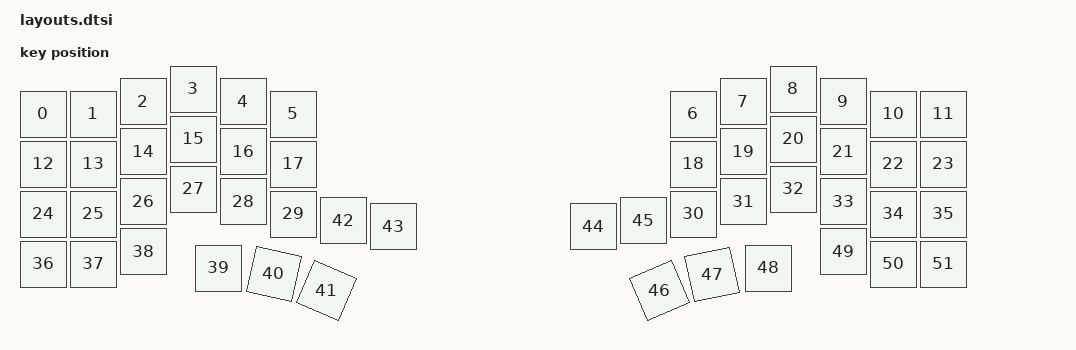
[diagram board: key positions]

#include <physical_layouts.dtsi>
/ {
    physical_layout0: physical_layout0 {
        compatible = "zmk,physical-layout";
        display-name = "Layout";
        keys
            = <&key_physical_attrs 100 100 0 100 0 0 0>
			,<&key_physical_attrs 100 100 100 100 0 0 0>
			,<&key_physical_attrs 100 100 200 75 0 0 0>
			,<&key_physical_attrs 100 100 300 50 0 0 0>
			,<&key_physical_attrs 100 100 400 75 0 0 0>
			,<&key_physical_attrs 100 100 500 100 0 0 0>
			,<&key_physical_attrs 100 100 1300 100 0 0 0>
			,<&key_physical_attrs 100 100 1400 75 0 0 0>
			,<&key_physical_attrs 100 100 1500 50 0 0 0>
			,<&key_physical_attrs 100 100 1600 75 0 0 0>
			,<&key_physical_attrs 100 100 1700 100 0 0 0>
			,<&key_physical_attrs 100 100 1800 100 0 0 0>
			,<&key_physical_attrs 100 100 0 200 0 0 0>
			,<&key_physical_attrs 100 100 100 200 0 0 0>
			,<&key_physical_attrs 100 100 200 175 0 0 0>
			,<&key_physical_attrs 100 100 300 150 0 0 0>
			,<&key_physical_attrs 100 100 400 175 0 0 0>
			,<&key_physical_attrs 100 100 500 200 0 0 0>
			,<&key_physical_attrs 100 100 1300 200 0 0 0>
			,<&key_physical_attrs 100 100 1400 175 0 0 0>
			,<&key_physical_attrs 100 100 1500 150 0 0 0>
			,<&key_physical_attrs 100 100 1600 175 0 0 0>
			,<&key_physical_attrs 100 100 1700 200 0 0 0>
			,<&key_physical_attrs 100 100 1800 200 0 0 0>
			,<&key_physical_attrs 100 100 0 300 0 0 0>
			,<&key_physical_attrs 100 100 100 300 0 0 0>
			,<&key_physical_attrs 100 100 200 275 0 0 0>
			,<&key_physical_attrs 100 100 300 250 0 0 0>
			,<&key_physical_attrs 100 100 400 275 0 0 0>
			,<&key_physical_attrs 100 100 500 300 0 0 0>
			,<&key_physical_attrs 100 100 1300 300 0 0 0>
			,<&key_physical_attrs 100 100 1400 275 0 0 0>
			,<&key_physical_attrs 100 100 1500 250 0 0 0>
			,<&key_physical_attrs 100 100 1600 275 0 0 0>
			,<&key_physical_attrs 100 100 1700 300 0 0 0>
			,<&key_physical_attrs 100 100 1800 300 0 0 0>
			,<&key_physical_attrs 100 100 0 400 0 0 0>
			,<&key_physical_attrs 100 100 100 400 0 0 0>
			,<&key_physical_attrs 100 100 200 375 0 0 0>
			,<&key_physical_attrs 100 100 350 408 0 0 0>
			,<&key_physical_attrs 100 100 473 411 1193 473 411>
			,<&key_physical_attrs 100 100 590 438 2300 590 438>
			,<&key_physical_attrs 100 100 600 313 0 0 0>
			,<&key_physical_attrs 100 100 700 325 0 0 0>
			,<&key_physical_attrs 100 100 1100 325 0 0 0>
			,<&key_physical_attrs 100 100 1200 313 0 0 0>
			,<&key_physical_attrs 100 100 1218 477 (-2300) 1218 477>
			,<&key_physical_attrs 100 100 1329 432 (-1193) 1329 432>
			,<&key_physical_attrs 100 100 1450 408 0 0 0>
			,<&key_physical_attrs 100 100 1600 375 0 0 0>
			,<&key_physical_attrs 100 100 1700 400 0 0 0>
			,<&key_physical_attrs 100 100 1800 400 0 0 0>
            ;
    };
};
    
